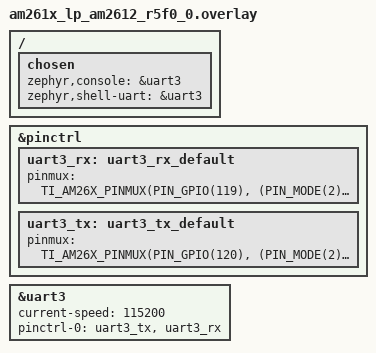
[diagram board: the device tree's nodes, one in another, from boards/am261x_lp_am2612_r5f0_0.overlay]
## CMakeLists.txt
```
#
# Copyright (c) 2026 Texas Instruments Incorporated
#
# SPDX-License-Identifier: Apache-2.0
#

cmake_minimum_required(VERSION 3.20.0)

find_package(Zephyr REQUIRED HINTS $ENV{ZEPHYR_BASE})

set(REMOTE_ZEPHYR_DIR ${CMAKE_CURRENT_BINARY_DIR}/../remote/zephyr)

if(NOT (CONFIG_BOARD_AM261X_LP_AM2612_R5F0_0))
	message("${BOARD} is not supported for this sample")
endif()

project(sample_xip_app)

if(CONFIG_INCLUDE_REMOTE_DIR)
	target_include_directories(zephyr_interface
		INTERFACE ${REMOTE_ZEPHYR_DIR}/include/public)
endif()

# Include blinky source code
target_sources(app PRIVATE src/main.c)

include(ExternalProject)
```

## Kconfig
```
# Copyright (c) 2026 Texas Instruments Incorporated
# SPDX-License-Identifier: Apache-2.0

source "Kconfig.zephyr"

config INCLUDE_REMOTE_DIR
	bool "Include remote project generated include directory"
	help
	  Include the remote project generated include directory in the
	  current project include directories.
```

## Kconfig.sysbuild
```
# Copyright 2026 Texas Instruments Incorporated
#
# SPDX-License-Identifier: Apache-2.0

source "share/sysbuild/Kconfig"

# This config is used to specify the remote core board
config REMOTE_CORE_BOARD
	string
	default "am261x_lp/am2612/r5f0_1" if $(BOARD) = "am261x_lp"
```

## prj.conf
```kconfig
# Enable GPIO
CONFIG_GPIO=y

#Enable Console
CONFIG_CONSOLE=y
CONFIG_UART_CONSOLE=y

# Include remote dir
CONFIG_INCLUDE_REMOTE_DIR=y

CONFIG_FLASH=y
CONFIG_XIP=y
```

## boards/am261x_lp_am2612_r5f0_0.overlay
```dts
/*
 * Copyright (c) 2026 Texas Instruments Incorporated
 *
 * SPDX-License-Identifier: Apache-2.0
 */

/ {
	chosen {
		zephyr,console = &uart3;
		zephyr,shell-uart = &uart3;
	};
};

&pinctrl {
		uart3_rx: uart3_rx_default {
			pinmux = <TI_AM26X_PINMUX(PIN_GPIO(119),
				  (PIN_MODE(2) | PIN_PULL_DISABLE | PIN_SLEW_RATE_LOW))>;
	};

	uart3_tx: uart3_tx_default {
			pinmux = <TI_AM26X_PINMUX(PIN_GPIO(120),
				  (PIN_MODE(2) | PIN_PULL_DISABLE | PIN_SLEW_RATE_LOW))>;
	};

};

&uart3 {
	status = "okay";
	current-speed = <115200>;
	pinctrl-0 = <&uart3_tx &uart3_rx>;
	pinctrl-names = "default";
};
```

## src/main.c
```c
/*
 * Copyright (c) 2026 Texas Instruments Incorporated
 *
 * SPDX-License-Identifier: Apache-2.0
 */

#include <stdio.h>
#include <zephyr/kernel.h>
#include <zephyr/drivers/gpio.h>

/* 1000 msec = 1 sec */
#define SLEEP_TIME_MS 1000

/* The devicetree node identifier for the "led0" alias. */
#define LED0_NODE DT_ALIAS(led0)

/*
 * A build error on this line means your board is unsupported.
 * See the sample documentation for information on how to fix this.
 */
static const struct gpio_dt_spec led = GPIO_DT_SPEC_GET(LED0_NODE, gpios);

int main(void)
{
	int ret;
	bool led_state = true;

	printf("Main Core Blinky Started\n");

	if (!gpio_is_ready_dt(&led)) {
		printf("LED device not ready - continuing with LED simulation\n");
		/* Continue with simulated LED behavior even if real LED isn't available */
	} else {
		ret = gpio_pin_configure_dt(&led, GPIO_OUTPUT_ACTIVE);
		if (ret < 0) {
			printf("Error %d: Failed to configure LED pin\n", ret);
			/* Continue with simulated LED behavior */
		}
	}

	/* Main loop */
	while (1) {
		/* Toggle real LED if available */
		if (gpio_is_ready_dt(&led)) {
			ret = gpio_pin_toggle_dt(&led);
			if (ret < 0) {
				printf("Error: Failed to toggle LED\n");
			}
		}

		/* Simulated LED state for console output */
		led_state = !led_state;
		printf("LED state: %s\n", led_state ? "ON" : "OFF");

		k_msleep(SLEEP_TIME_MS);
	}
	return 0;
}
```
